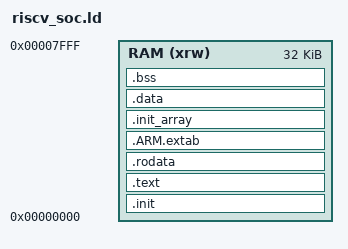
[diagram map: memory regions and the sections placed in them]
/* Entry Point */
ENTRY(Reset)

/* Highest address of the user mode stack */
_estack = ORIGIN(RAM) + LENGTH(RAM);	/* end of "RAM" Ram type memory */

_Min_Heap_Size = 0x200;	/* required amount of heap  */
_Min_Stack_Size = 0x400;	/* required amount of stack */

/* Memories definition */
MEMORY
{
  RAM    (xrw)    : ORIGIN = 0x00000000,   LENGTH = 32K
}

/* Sections */
SECTIONS
{
  /* The startup code into "FLASH" Rom type memory */
  .init :
  {
    _FLASH_START = .;
    . = ALIGN(4);
    KEEP(*(.Reset)) /* Startup code */
    KEEP(*(.IRQ_entry)) /* Startup code */
    /*init_s.o(.text)*/
    . = ALIGN(4);
  } >RAM

  /* The program code and other data into "FLASH" Rom type memory */
  .text :
  {
    . = ALIGN(4);
    *(.text)           /* .text sections (code) */
    *(.text*)          /* .text* sections (code) */
    *(.glue_7)         /* glue arm to thumb code */
    *(.glue_7t)        /* glue thumb to arm code */
    *(.eh_frame)

    KEEP (*(.init))
    KEEP (*(.fini))

    . = ALIGN(4);
    _etext = .;        /* define a global symbols at end of code */
  } >RAM

  /* Constant data into "FLASH" Rom type memory */
  .rodata :
  {
    . = ALIGN(4);
    *(.rodata)         /* .rodata sections (constants, strings, etc.) */
    *(.rodata*)        /* .rodata* sections (constants, strings, etc.) */
    . = ALIGN(4);
  } >RAM

  .ARM.extab   : { 
    . = ALIGN(4);
    *(.ARM.extab* .gnu.linkonce.armextab.*)
    . = ALIGN(4);
  } >RAM

  .init_array :
  {
    . = ALIGN(4);
    PROVIDE_HIDDEN (__init_array_start = .);
	__ctors_start__ = .;
    KEEP (*(SORT(.init_array.*)))
    KEEP (*(.init_array*))
	*crtbegin.o(.ctors)
	*crtbegin?.o(.ctors)
	*(EXCLUDE_FILE(*crtend?.o *crtend.o) .ctors)
	*(SORT(.ctors.*))
	*(.ctors)
	__ctors_end__ = .;
    PROVIDE_HIDDEN (__init_array_end = .);
    . = ALIGN(4);
  } >RAM

  /* Used by the startup to initialize data */
  _sidata = LOADADDR(.data);

  /* Initialized data sections into "RAM" Ram type memory */
  .data : 
  {
    . = ALIGN(4);
    _sdata = .;        /* create a global symbol at data start */
    *(.data)           /* .data sections */
    *(.data*)          /* .data* sections */

    . = ALIGN(4);
    _edata = .;        /* define a global symbol at data end */
    
  } >RAM

  /* Uninitialized data section into "RAM" Ram type memory */
  . = ALIGN(4);
  .bss :
  {
    /* This is used by the startup in order to initialize the .bss section */
    _sbss = .;         /* define a global symbol at bss start */
    __bss_start__ = _sbss;
    *(.bss)
    *(.bss*)
    *(.sbss)
    *(.sbss*)
    *(COMMON)

    . = ALIGN(4);
    _ebss = .;         /* define a global symbol at bss end */
    __bss_end__ = _ebss;
  } >RAM
}
